VERSION "Twizy BMS_1 example, from OVMS DBC primer"

NS_ :

BS_:

BU_: Vector__XXX

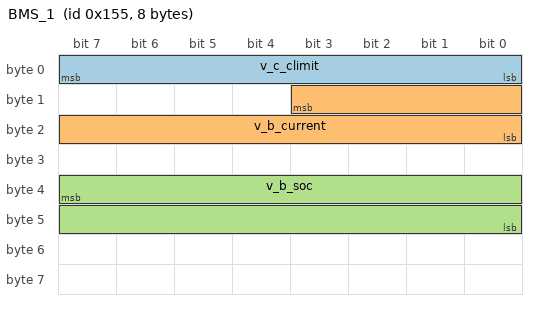
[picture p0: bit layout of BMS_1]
BO_ 341 BMS_1: 8 Vector__XXX
 SG_ v_c_climit : 7|8@0+ (5,0) [0|35] "A" Vector__XXX
 SG_ v_b_current : 11|12@0+ (-0.25,500) [-500|1000] "A" Vector__XXX
 SG_ v_b_soc : 39|16@0+ (0.0025,0) [0|100] "%" Vector__XXX
